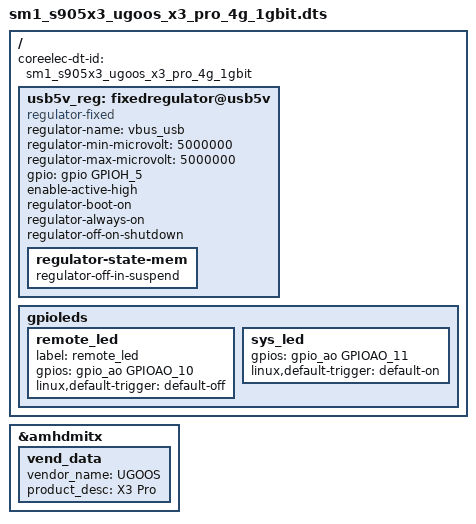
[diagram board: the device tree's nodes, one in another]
#include "sm1_s905x3_4g_1gbit.dts"

/{
	coreelec-dt-id = "sm1_s905x3_ugoos_x3_pro_4g_1gbit";

	usb5v_reg: fixedregulator@usb5v {
		compatible = "regulator-fixed";
								regulator-name = "vbus_usb";
								regulator-min-microvolt = <5000000>;
								regulator-max-microvolt = <5000000>;
								gpio = <&gpio GPIOH_5 GPIO_ACTIVE_HIGH>;
								enable-active-high;
								regulator-boot-on;
								regulator-always-on;
								regulator-off-on-shutdown;

								regulator-state-mem {
									regulator-off-in-suspend;
								};
	};

	gpioleds {
		/* blue led */
		remote_led {
			label = "remote_led";
			gpios = <&gpio_ao GPIOAO_10 GPIO_ACTIVE_HIGH>;
			linux,default-trigger = "default-off";
		};

		/* red led */
		sys_led {
				gpios=<&gpio_ao GPIOAO_11 GPIO_ACTIVE_HIGH>;
				linux,default-trigger = "default-on";
		};
	};
};

&amhdmitx {
	vend_data {
		vendor_name = "UGOOS";
		product_desc = "X3 Pro";
	};
};
